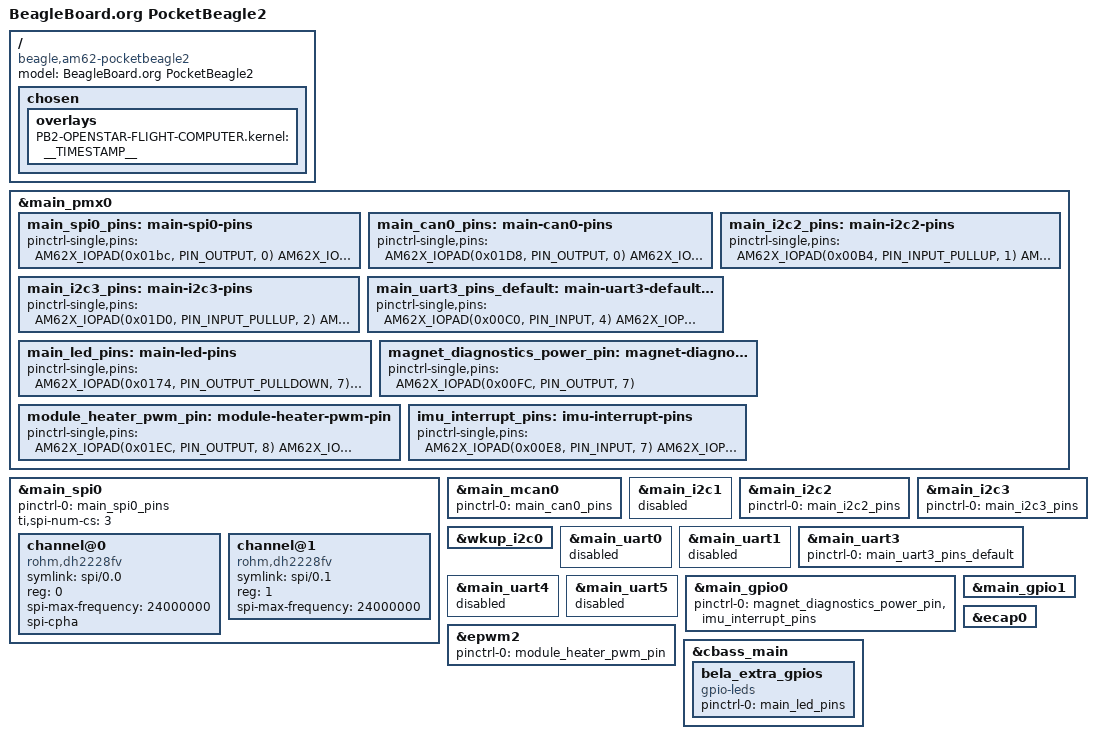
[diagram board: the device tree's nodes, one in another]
// SPDX-License-Identifier: GPL-2.0
/*
 * Copyright (C) 2022 BeagleBoard.org - https://beagleboard.org/
 *
 * https://docs.beagleboard.io/latest/boards/capes/cape-interface-spec.html#i2c
 */
#include <dt-bindings/leds/common.h>
#include <dt-bindings/gpio/gpio.h>
#include "ti/k3-pinctrl.h"

/dts-v1/;
/plugin/;

/*
 * Helper to show loaded overlays under: /proc/device-tree/chosen/overlays/
 */
/{
	compatible = "beagle,am62-pocketbeagle2", "ti,am625";
	model = "BeagleBoard.org PocketBeagle2";

	chosen {
		overlays {
			PB2-OPENSTAR-FLIGHT-COMPUTER.kernel = __TIMESTAMP__;
		};
	};
};

// many definitions from pinmux/board/pocketbeagle2/pocketbeagle2-pinmux.dts
&main_pmx0 {
	main_spi0_pins: main-spi0-pins {
		pinctrl-single,pins = <
			AM62X_IOPAD(0x01bc, PIN_OUTPUT, 0) /* P2.29 (A14) SPI0_CLK */
			AM62X_IOPAD(0x01c0, PIN_INPUT, 0) /* P2.27 (B13) SPI0_MISO */
			AM62X_IOPAD(0x01c4, PIN_OUTPUT, 0) /* P2.25 SPI0_MOSI */
			AM62X_IOPAD(0x01b4, PIN_OUTPUT, 0) /* P2.31 (A13) SPI0_CS0 */
			AM62X_IOPAD(0x01B8, PIN_OUTPUT, 0) /* P2.36 (C13) SPI0_CS1 */
		>;
	};
	main_can0_pins: main-can0-pins {
		pinctrl-single,pins = <
			AM62X_IOPAD(0x01D8, PIN_OUTPUT, 0) /* P2.05 (C15) MCAN0_TX */
			AM62X_IOPAD(0x01DC, PIN_INPUT, 0) /*  P2.07 (E15) MCAN0_RX */
		>;
	};
	main_i2c2_pins: main-i2c2-pins {
		pinctrl-single,pins = <
			AM62X_IOPAD(0x00B4, PIN_INPUT_PULLUP, 1) /* P1.26 (K24) I2C2_SDA */
			AM62X_IOPAD(0x00B0, PIN_INPUT_PULLUP, 1) /* P1.28 (K22) I2C2_SCL */
		>;
	};
	main_i2c3_pins: main-i2c3-pins {
		pinctrl-single,pins = <
			AM62X_IOPAD(0x01D0, PIN_INPUT_PULLUP, 2) /* P2.09 (A15) I2C3_SCL */
			AM62X_IOPAD(0x01D4, PIN_INPUT_PULLUP, 2) /* P2.11 (B15) I2C3_SDA */
		>;
	};
	main_uart3_pins_default: main-uart3-default-pins {
		pinctrl-single,pins = <
			AM62X_IOPAD(0x00C0, PIN_INPUT, 4) /* P2.06 (W25) UART3_RXD */
			AM62X_IOPAD(0x00C4, PIN_OUTPUT, 4) /* P2.08 (W24) UART3_TXD */
		>;
	};
	main_led_pins: main-led-pins {
		pinctrl-single,pins = <
		AM62X_IOPAD(0x0174, PIN_OUTPUT_PULLDOWN, 7) /* P2.10 - LED C*/
		AM62X_IOPAD(0x00B8, PIN_OUTPUT_PULLDOWN, 7) /* P2.02 - LED A*/
		AM62X_IOPAD(0x00BC, PIN_OUTPUT_PULLDOWN, 7) /* P2.04 - LED B*/
		/* AM62X_IOPAD(0x0160, PIN_OUTPUT_PULLDOWN, 7) */ /* P2.01 - BUZZER*/
		>;
	};

	magnet_diagnostics_power_pin: magnet-diagnostics-power-pin {
		pinctrl-single,pins = <
		AM62X_IOPAD(0x00FC, PIN_OUTPUT, 7) /*P1.29*/
		>;
	};

  module_heater_pwm_pin: module-heater-pwm-pin {
    pinctrl-single,pins = <
    AM62X_IOPAD(0x01EC, PIN_OUTPUT, 8) /*P1.33*/
    AM62X_IOPAD(0x00E4, PIN_DISABLE, 7) /* (AA23) VOUT0_DATA11.GPIO0_56 */
    >;
  };

	/* LSM6DS3TR-C interrupt outputs. Without these the pads keep their reset
	 * mux, so the GPIOs never see the IMU's FIFO watermark and fc_imu has to
	 * fall back to timed reads. Both INT pins are push-pull active high.
	 */
	imu_interrupt_pins: imu-interrupt-pins {
		pinctrl-single,pins = <
		AM62X_IOPAD(0x00E8, PIN_INPUT, 7) /* P2.32 (AB25) VOUT0_DATA12.GPIO0_57 - IMU INT1 */
		AM62X_IOPAD(0x00F4, PIN_INPUT, 7) /* P2.34 (AA21) VOUT0_DATA15.GPIO0_60 - IMU INT2 */
		>;
	};
};

&main_spi0 {
	pinctrl-names = "default";
	pinctrl-0 = <&main_spi0_pins>;
	status = "okay";
	#address-cells = <1>;
	#size-cells = <0>;
	ti,spi-num-cs = <3>;

	channel@0 {
		compatible = "rohm,dh2228fv";
		#address-cells = <1>;
		#size-cells = <0>;
		symlink = "spi/0.0";
		reg = <0>;
		spi-max-frequency = <24000000>;
		spi-cpha;
	};
        channel@1 {
                compatible = "rohm,dh2228fv";
		#address-cells = <1>;
		#size-cells = <0>;
		symlink = "spi/0.1";
		reg = <1>;
                spi-max-frequency = <24000000>;
        };

};
&main_mcan0 {
    pinctrl-names = "default";
    pinctrl-0 = <&main_can0_pins>;
    status = "okay";
};

&main_i2c1 {
    status = "disabled";
};

&main_i2c2 {
    pinctrl-names = "default";
    pinctrl-0 = <&main_i2c2_pins>;
    status = "okay";
};

&main_i2c3 {
    pinctrl-names = "default";
    pinctrl-0 = <&main_i2c3_pins>;
    status = "okay";
};

&wkup_i2c0 {
    status = "okay";
};

&main_uart0 {
	status = "disabled";
};

&main_uart1 {
	status = "disabled";
};

&main_uart3 {
        pinctrl-names = "default";
        pinctrl-0 = <&main_uart3_pins_default>;
        bootph-all;
        status = "okay";
};

&main_uart4 {
	status = "disabled";
};

&main_uart5 {
	status = "disabled";
};
&main_gpio0 {
	status = "okay";
	pinctrl-names = "default";
	pinctrl-0 = <&magnet_diagnostics_power_pin &imu_interrupt_pins>;
};
&main_gpio1 {
	status = "okay";
};

&ecap0 {
	status = "okay";
};

&epwm2 {
  status = "okay";
  pinctrl-names = "default";
  pinctrl-0 = <&module_heater_pwm_pin>;
};

&cbass_main {
    bela_extra_gpios {
        compatible = "gpio-leds";
        pinctrl-0 = <&main_led_pins>;
        pinctrl-names = "default";
    };
};
